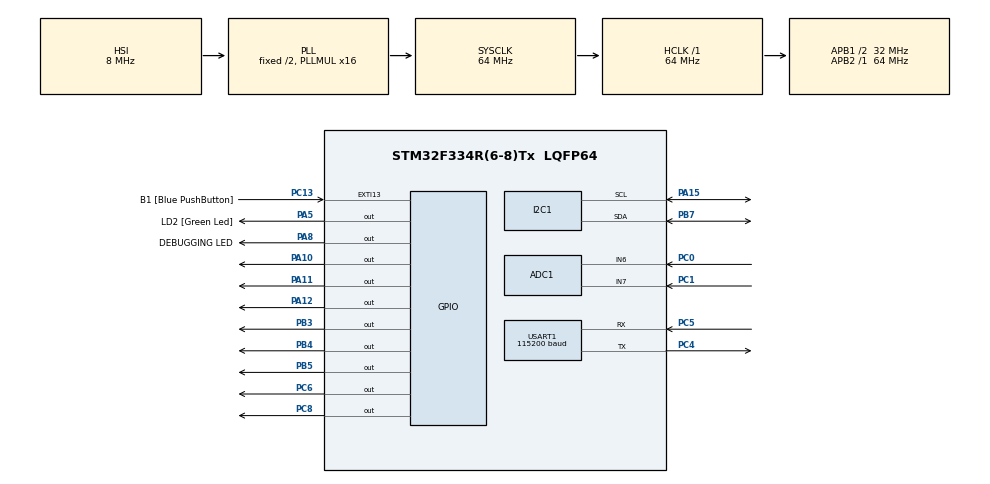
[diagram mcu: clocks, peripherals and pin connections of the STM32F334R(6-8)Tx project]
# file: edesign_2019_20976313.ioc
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ADC1.Channel-0\#ChannelRegularConversion=ADC_CHANNEL_6
ADC1.Channel-1\#ChannelRegularConversion=ADC_CHANNEL_7
ADC1.ClockPrescaler=ADC_CLOCK_SYNC_PCLK_DIV4
ADC1.ContinuousConvMode=ENABLE
ADC1.DMAContinuousRequests=ENABLE
ADC1.NbrOfConversion=2
ADC1.NbrOfConversionFlag=1
ADC1.Offset-0\#ChannelRegularConversion=0
ADC1.Offset-1\#ChannelRegularConversion=0
ADC1.OffsetNumber-0\#ChannelRegularConversion=ADC_OFFSET_NONE
ADC1.OffsetNumber-1\#ChannelRegularConversion=ADC_OFFSET_NONE
ADC1.Rank-0\#ChannelRegularConversion=1
ADC1.Rank-1\#ChannelRegularConversion=2
ADC1.SamplingTime-0\#ChannelRegularConversion=ADC_SAMPLETIME_181CYCLES_5
ADC1.SamplingTime-1\#ChannelRegularConversion=ADC_SAMPLETIME_181CYCLES_5
ADC1.SubFamily=STM32F334x8
ADC1.master=1
Dma.ADC1.0.Direction=DMA_PERIPH_TO_MEMORY
Dma.ADC1.0.Instance=DMA1_Channel1
Dma.ADC1.0.MemDataAlignment=DMA_MDATAALIGN_WORD
Dma.ADC1.0.MemInc=DMA_MINC_ENABLE
Dma.ADC1.0.Mode=DMA_CIRCULAR
Dma.ADC1.0.PeriphDataAlignment=DMA_PDATAALIGN_WORD
Dma.ADC1.0.PeriphInc=DMA_PINC_DISABLE
Dma.ADC1.0.Priority=DMA_PRIORITY_HIGH
Dma.Request0=ADC1
Mcu.Family=STM32F3
Mcu.Name=STM32F334R(6-8)Tx
Mcu.Package=LQFP64
NVIC.DMA1_Channel1_IRQn=true\:0\:0\:false\:false\:true\:false\:true
NVIC.PriorityGroup=NVIC_PRIORITYGROUP_0
NVIC.TIM2_IRQn=true\:0\:0\:false\:false\:true\:true\:true
NVIC.TIM3_IRQn=true\:0\:0\:false\:false\:true\:true\:true
NVIC.USART1_IRQn=true\:0\:0\:false\:false\:true\:true\:true
PA10.Signal=GPIO_Output
PA11.Signal=GPIO_Output
PA12.Signal=GPIO_Output
PA13.GPIO_Label=TMS
PA13.Mode=Serial_Wire
PA13.Signal=SYS_JTMS-SWDIO
PA14.GPIO_Label=TCK
PA14.Mode=Serial_Wire
PA14.Signal=SYS_JTCK-SWCLK
PA15.Mode=I2C
PA15.Signal=I2C1_SCL
PA5.GPIO_Label=LD2 [Green Led]
PA5.Signal=GPIO_Output
PA8.GPIO_Label=DEBUGGING LED
PA8.Signal=GPIO_Output
PB3.Signal=GPIO_Output
PB4.Signal=GPIO_Output
PB5.Signal=GPIO_Output
PB7.Mode=I2C
PB7.Signal=I2C1_SDA
PC0.Signal=ADCx_IN6
PC1.Signal=ADCx_IN7
PC13.GPIO_Label=B1 [Blue PushButton]
PC13.GPIO_ModeDefaultEXTI=GPIO_MODE_IT_FALLING
PC13.Signal=GPXTI13
PC14\ /\ OSC32_IN.Mode=LSE-External-Oscillator
PC14\ /\ OSC32_IN.Signal=RCC_OSC32_IN
PC15\ /\ OSC32_OUT.GPIO_Label=RCC_OSC32_OUT
PC15\ /\ OSC32_OUT.Mode=LSE-External-Oscillator
PC15\ /\ OSC32_OUT.Signal=RCC_OSC32_OUT
PC4.Mode=Asynchronous
PC4.Signal=USART1_TX
PC5.Mode=Asynchronous
PC5.Signal=USART1_RX
PC6.Signal=GPIO_Output
PC8.Signal=GPIO_Output
PF0\ /\ OSC_IN.Mode=HSE-External-Clock-Source
PF0\ /\ OSC_IN.Signal=RCC_OSC_IN
PF1\ /\ OSC_OUT.Signal=RCC_OSC_OUT
ProjectManager.HeapSize=0x200
ProjectManager.StackSize=0x400
ProjectManager.TargetToolchain=TrueSTUDIO
RCC.AHBFreq_Value=64000000
RCC.APB1CLKDivider=RCC_HCLK_DIV2
RCC.APB1Freq_Value=32000000
RCC.APB1TimFreq_Value=64000000
RCC.APB2Freq_Value=64000000
RCC.APB2TimFreq_Value=64000000
RCC.CortexFreq_Value=64000000
RCC.FLatency-AdvancedSettings=FLASH_LATENCY_2
RCC.HCLKFreq_Value=64000000
RCC.HSE_VALUE=8000000
RCC.HSI_VALUE=8000000
RCC.PLLMUL=RCC_PLL_MUL16
RCC.SYSCLKFreq_VALUE=64000000
RCC.SYSCLKSourceVirtual=RCC_SYSCLKSOURCE_PLLCLK
SH.ADCx_IN6.0=ADC1_IN6,IN6-Single-Ended
SH.ADCx_IN7.0=ADC1_IN7,IN7-Single-Ended
TIM2.AutoReloadPreload=TIM_AUTORELOAD_PRELOAD_ENABLE
TIM2.ClockDivision=TIM_CLOCKDIVISION_DIV4
TIM2.Period=999
TIM2.Prescaler=63999
TIM3.AutoReloadPreload=TIM_AUTORELOAD_PRELOAD_ENABLE
TIM3.Period=99
TIM3.Prescaler=32000
USART1.BaudRate=115200
USART1.VirtualMode-Asynchronous=VM_ASYNC
VP_TIM2_VS_ClockSourceINT.Mode=Internal
VP_TIM3_VS_ClockSourceINT.Mode=Internal
board=NUCLEO-F334R8

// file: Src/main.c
/* USER CODE BEGIN Header */
/**
  ******************************************************************************
  * @file           : main.c
  * @brief          : Main program body
  ******************************************************************************
  * @attention
  *
  * <h2><center>&copy; Copyright (c) 2019 STMicroelectronics.
  * All rights reserved.</center></h2>
  *
  * This software component is licensed by ST under BSD 3-Clause license,
  * the "License"; You may not use this file except in compliance with the
  * License. You may obtain a copy of the License at:
  *                        opensource.org/licenses/BSD-3-Clause
  *
  ******************************************************************************
  */

/*
 * File: main.c
 * Author: 20976313
 *
 */

/* USER CODE END Header */

#include "main.h"

/* USER CODE BEGIN Includes */
#include "prog_def.h"
/* USER CODE END Includes */

ADC_HandleTypeDef hadc1;
DMA_HandleTypeDef hdma_adc1;
I2C_HandleTypeDef hi2c1;
TIM_HandleTypeDef htim2;
TIM_HandleTypeDef htim3;
UART_HandleTypeDef huart1;

void SystemClock_Config(void);
static void MX_GPIO_Init(void);
static void MX_DMA_Init(void);
static void MX_ADC1_Init(void);
static void MX_USART1_UART_Init(void);
static void MX_TIM2_Init(void);
static void MX_TIM3_Init(void);
static void MX_I2C1_Init(void);

int main(void)
{

  /* MCU Configuration--------------------------------------------------------*/

  /* Reset of all peripherals, Initializes the Flash interface and the Systick. */
  HAL_Init();

  /* Configure the system clock */
  SystemClock_Config();

  /* Initialize all configured peripherals */
  MX_GPIO_Init();
  MX_DMA_Init();
  MX_ADC1_Init();
  MX_USART1_UART_Init();
  MX_TIM2_Init();
  MX_TIM3_Init();
  MX_I2C1_Init();
  /* USER CODE BEGIN 2 */
  dwt_init();
  init_sys();
  //HAL_I2C_Init(&hi2c1);
  /* USER CODE END 2 */

  /* Infinite loop */
  /* USER CODE BEGIN WHILE */
  while (1)
  {
	system_loop();
    /* USER CODE END WHILE */

  }
}

void SystemClock_Config(void)
{
  RCC_OscInitTypeDef RCC_OscInitStruct = {0};
  RCC_ClkInitTypeDef RCC_ClkInitStruct = {0};
  RCC_PeriphCLKInitTypeDef PeriphClkInit = {0};

  /** Initializes the CPU, AHB and APB busses clocks
  */
  RCC_OscInitStruct.OscillatorType = RCC_OSCILLATORTYPE_HSI;
  RCC_OscInitStruct.HSIState = RCC_HSI_ON;
  RCC_OscInitStruct.HSICalibrationValue = RCC_HSICALIBRATION_DEFAULT;
  RCC_OscInitStruct.PLL.PLLState = RCC_PLL_ON;
  RCC_OscInitStruct.PLL.PLLSource = RCC_PLLSOURCE_HSI;
  RCC_OscInitStruct.PLL.PLLMUL = RCC_PLL_MUL16;
  if (HAL_RCC_OscConfig(&RCC_OscInitStruct) != HAL_OK)
  {
    Error_Handler();
  }
  /** Initializes the CPU, AHB and APB busses clocks
  */
  RCC_ClkInitStruct.ClockType = RCC_CLOCKTYPE_HCLK|RCC_CLOCKTYPE_SYSCLK
                              |RCC_CLOCKTYPE_PCLK1|RCC_CLOCKTYPE_PCLK2;
  RCC_ClkInitStruct.SYSCLKSource = RCC_SYSCLKSOURCE_PLLCLK;
  RCC_ClkInitStruct.AHBCLKDivider = RCC_SYSCLK_DIV1;
  RCC_ClkInitStruct.APB1CLKDivider = RCC_HCLK_DIV2;
  RCC_ClkInitStruct.APB2CLKDivider = RCC_HCLK_DIV1;

  if (HAL_RCC_ClockConfig(&RCC_ClkInitStruct, FLASH_LATENCY_2) != HAL_OK)
  {
    Error_Handler();
  }
  PeriphClkInit.PeriphClockSelection = RCC_PERIPHCLK_USART1|RCC_PERIPHCLK_I2C1;
  PeriphClkInit.Usart1ClockSelection = RCC_USART1CLKSOURCE_PCLK1;
  PeriphClkInit.I2c1ClockSelection = RCC_I2C1CLKSOURCE_HSI;
  if (HAL_RCCEx_PeriphCLKConfig(&PeriphClkInit) != HAL_OK)
  {
    Error_Handler();
  }
}

static void MX_ADC1_Init(void)
{

  ADC_MultiModeTypeDef multimode = {0};
  ADC_ChannelConfTypeDef sConfig = {0};

  /** Common config
  */
  hadc1.Instance = ADC1;
  hadc1.Init.ClockPrescaler = ADC_CLOCK_SYNC_PCLK_DIV4;
  hadc1.Init.Resolution = ADC_RESOLUTION_12B;
  hadc1.Init.ScanConvMode = ADC_SCAN_ENABLE;
  hadc1.Init.ContinuousConvMode = ENABLE;
  hadc1.Init.DiscontinuousConvMode = DISABLE;
  hadc1.Init.ExternalTrigConvEdge = ADC_EXTERNALTRIGCONVEDGE_NONE;
  hadc1.Init.ExternalTrigConv = ADC_SOFTWARE_START;
  hadc1.Init.DataAlign = ADC_DATAALIGN_RIGHT;
  hadc1.Init.NbrOfConversion = 2;
  hadc1.Init.DMAContinuousRequests = ENABLE;
  hadc1.Init.EOCSelection = ADC_EOC_SINGLE_CONV;
  hadc1.Init.LowPowerAutoWait = DISABLE;
  hadc1.Init.Overrun = ADC_OVR_DATA_OVERWRITTEN;
  if (HAL_ADC_Init(&hadc1) != HAL_OK)
  {
    Error_Handler();
  }
  /** Configure the ADC multi-mode
  */
  multimode.Mode = ADC_MODE_INDEPENDENT;
  if (HAL_ADCEx_MultiModeConfigChannel(&hadc1, &multimode) != HAL_OK)
  {
    Error_Handler();
  }
  /** Configure Regular Channel
  */
  sConfig.Channel = ADC_CHANNEL_6;
  sConfig.Rank = ADC_REGULAR_RANK_1;
  sConfig.SingleDiff = ADC_SINGLE_ENDED;
  sConfig.SamplingTime = ADC_SAMPLETIME_181CYCLES_5;
  sConfig.OffsetNumber = ADC_OFFSET_NONE;
  sConfig.Offset = 0;
  if (HAL_ADC_ConfigChannel(&hadc1, &sConfig) != HAL_OK)
  {
    Error_Handler();
  }
  /** Configure Regular Channel
  */
  sConfig.Channel = ADC_CHANNEL_7;
  sConfig.Rank = ADC_REGULAR_RANK_2;
  if (HAL_ADC_ConfigChannel(&hadc1, &sConfig) != HAL_OK)
  {
    Error_Handler();
  }

}

static void MX_I2C1_Init(void)
{

  hi2c1.Instance = I2C1;
  hi2c1.Init.Timing = 0x2000090E;
  hi2c1.Init.OwnAddress1 = 0;
  hi2c1.Init.AddressingMode = I2C_ADDRESSINGMODE_7BIT;
  hi2c1.Init.DualAddressMode = I2C_DUALADDRESS_DISABLE;
  hi2c1.Init.OwnAddress2 = 0;
  hi2c1.Init.OwnAddress2Masks = I2C_OA2_NOMASK;
  hi2c1.Init.GeneralCallMode = I2C_GENERALCALL_DISABLE;
  hi2c1.Init.NoStretchMode = I2C_NOSTRETCH_DISABLE;
  if (HAL_I2C_Init(&hi2c1) != HAL_OK)
  {
    Error_Handler();
  }
  /** Configure Analogue filter
  */
  if (HAL_I2CEx_ConfigAnalogFilter(&hi2c1, I2C_ANALOGFILTER_ENABLE) != HAL_OK)
  {
    Error_Handler();
  }
  /** Configure Digital filter
  */
  if (HAL_I2CEx_ConfigDigitalFilter(&hi2c1, 0) != HAL_OK)
  {
    Error_Handler();
  }

}

static void MX_TIM2_Init(void)
{

  TIM_ClockConfigTypeDef sClockSourceConfig = {0};
  TIM_MasterConfigTypeDef sMasterConfig = {0};

  htim2.Instance = TIM2;
  htim2.Init.Prescaler = 63999;
  htim2.Init.CounterMode = TIM_COUNTERMODE_UP;
  htim2.Init.Period = 999;
  htim2.Init.ClockDivision = TIM_CLOCKDIVISION_DIV4;
  htim2.Init.AutoReloadPreload = TIM_AUTORELOAD_PRELOAD_ENABLE;
  if (HAL_TIM_Base_Init(&htim2) != HAL_OK)
  {
    Error_Handler();
  }
  sClockSourceConfig.ClockSource = TIM_CLOCKSOURCE_INTERNAL;
  if (HAL_TIM_ConfigClockSource(&htim2, &sClockSourceConfig) != HAL_OK)
  {
    Error_Handler();
  }
  sMasterConfig.MasterOutputTrigger = TIM_TRGO_RESET;
  sMasterConfig.MasterSlaveMode = TIM_MASTERSLAVEMODE_DISABLE;
  if (HAL_TIMEx_MasterConfigSynchronization(&htim2, &sMasterConfig) != HAL_OK)
  {
    Error_Handler();
  }

}

static void MX_TIM3_Init(void)
{

  TIM_ClockConfigTypeDef sClockSourceConfig = {0};
  TIM_MasterConfigTypeDef sMasterConfig = {0};

  htim3.Instance = TIM3;
  htim3.Init.Prescaler = 32000;
  htim3.Init.CounterMode = TIM_COUNTERMODE_UP;
  htim3.Init.Period = 99;
  htim3.Init.ClockDivision = TIM_CLOCKDIVISION_DIV1;
  htim3.Init.AutoReloadPreload = TIM_AUTORELOAD_PRELOAD_ENABLE;
  if (HAL_TIM_Base_Init(&htim3) != HAL_OK)
  {
    Error_Handler();
  }
  sClockSourceConfig.ClockSource = TIM_CLOCKSOURCE_INTERNAL;
  if (HAL_TIM_ConfigClockSource(&htim3, &sClockSourceConfig) != HAL_OK)
  {
    Error_Handler();
  }
  sMasterConfig.MasterOutputTrigger = TIM_TRGO_RESET;
  sMasterConfig.MasterSlaveMode = TIM_MASTERSLAVEMODE_DISABLE;
  if (HAL_TIMEx_MasterConfigSynchronization(&htim3, &sMasterConfig) != HAL_OK)
  {
    Error_Handler();
  }

}

static void MX_USART1_UART_Init(void)
{

  huart1.Instance = USART1;
  huart1.Init.BaudRate = 115200;
  huart1.Init.WordLength = UART_WORDLENGTH_8B;
  huart1.Init.StopBits = UART_STOPBITS_1;
  huart1.Init.Parity = UART_PARITY_NONE;
  huart1.Init.Mode = UART_MODE_TX_RX;
  huart1.Init.HwFlowCtl = UART_HWCONTROL_NONE;
  huart1.Init.OverSampling = UART_OVERSAMPLING_16;
  huart1.Init.OneBitSampling = UART_ONE_BIT_SAMPLE_DISABLE;
  huart1.AdvancedInit.AdvFeatureInit = UART_ADVFEATURE_NO_INIT;
  if (HAL_UART_Init(&huart1) != HAL_OK)
  {
    Error_Handler();
  }

}

static void MX_DMA_Init(void)
{
  /* DMA controller clock enable */
  __HAL_RCC_DMA1_CLK_ENABLE();

  /* DMA interrupt init */
  /* DMA1_Channel1_IRQn interrupt configuration */
  HAL_NVIC_SetPriority(DMA1_Channel1_IRQn, 0, 0);
  HAL_NVIC_EnableIRQ(DMA1_Channel1_IRQn);

}

static void MX_GPIO_Init(void)
{
  GPIO_InitTypeDef GPIO_InitStruct = {0};

  /* GPIO Ports Clock Enable */
  __HAL_RCC_GPIOC_CLK_ENABLE();
  __HAL_RCC_GPIOF_CLK_ENABLE();
  __HAL_RCC_GPIOA_CLK_ENABLE();
  __HAL_RCC_GPIOB_CLK_ENABLE();

  /*Configure GPIO pin Output Level */
  HAL_GPIO_WritePin(GPIOA, LD2_Pin|DEBUGGING_LED_Pin|GPIO_PIN_10|GPIO_PIN_11
                          |GPIO_PIN_12, GPIO_PIN_RESET);

  /*Configure GPIO pin Output Level */
  HAL_GPIO_WritePin(GPIOC, GPIO_PIN_6|GPIO_PIN_8, GPIO_PIN_RESET);

  /*Configure GPIO pin Output Level */
  HAL_GPIO_WritePin(GPIOB, GPIO_PIN_3|GPIO_PIN_4|GPIO_PIN_5, GPIO_PIN_RESET);

  /*Configure GPIO pin : B1_Pin */
  GPIO_InitStruct.Pin = B1_Pin;
  GPIO_InitStruct.Mode = GPIO_MODE_IT_FALLING;
  GPIO_InitStruct.Pull = GPIO_NOPULL;
  HAL_GPIO_Init(B1_GPIO_Port, &GPIO_InitStruct);

  /*Configure GPIO pins : LD2_Pin DEBUGGING_LED_Pin PA10 PA11
                           PA12 */
  GPIO_InitStruct.Pin = LD2_Pin|DEBUGGING_LED_Pin|GPIO_PIN_10|GPIO_PIN_11
                          |GPIO_PIN_12;
  GPIO_InitStruct.Mode = GPIO_MODE_OUTPUT_PP;
  GPIO_InitStruct.Pull = GPIO_NOPULL;
  GPIO_InitStruct.Speed = GPIO_SPEED_FREQ_LOW;
  HAL_GPIO_Init(GPIOA, &GPIO_InitStruct);

  /*Configure GPIO pins : PC6 PC8 */
  GPIO_InitStruct.Pin = GPIO_PIN_6|GPIO_PIN_8;
  GPIO_InitStruct.Mode = GPIO_MODE_OUTPUT_PP;
  GPIO_InitStruct.Pull = GPIO_NOPULL;
  GPIO_InitStruct.Speed = GPIO_SPEED_FREQ_LOW;
  HAL_GPIO_Init(GPIOC, &GPIO_InitStruct);

  /*Configure GPIO pins : PB3 PB4 PB5 */
  GPIO_InitStruct.Pin = GPIO_PIN_3|GPIO_PIN_4|GPIO_PIN_5;
  GPIO_InitStruct.Mode = GPIO_MODE_OUTPUT_PP;
  GPIO_InitStruct.Pull = GPIO_NOPULL;
  GPIO_InitStruct.Speed = GPIO_SPEED_FREQ_LOW;
  HAL_GPIO_Init(GPIOB, &GPIO_InitStruct);

}

void Error_Handler(void)
{
}

/************************ (C) COPYRIGHT STMicroelectronics *****END OF FILE****/
